# PIC32MX570F512L register map
Vendor: Microchip
Registers are 32-bit, read-write, reset 0x0 unless marked. A register's access mark holds for its fields unless they carry their own. Addresses are absolute, and some are shared; only a register's first bit layout is shown; [hi:lo] are bit positions; {n}, {i} and the like mark numbered series.

## TRAN_Ports
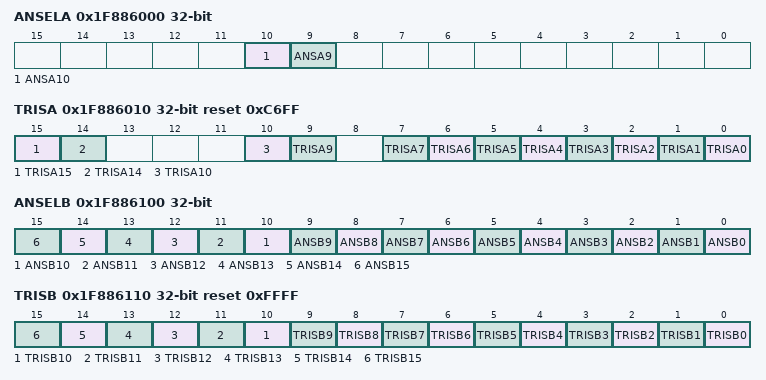
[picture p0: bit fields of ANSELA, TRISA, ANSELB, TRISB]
0x1F886000 ANSELA reset not defined — (power-on value ---------------------xx---------)
  [10] ANSA10, [9] ANSA9
0x1F886010 TRISA reset 0xC6FF
  [15] TRISA15, [14] TRISA14, [10] TRISA10, [9] TRISA9, [n] TRISA{n} (n=0..7)
0x1F886100 ANSELB reset not defined — (power-on value ----------------xxxxxxxxxxxxxxxx)
  [n] ANSB{n} (n=0..15)
0x1F886110 TRISB reset 0xFFFF
  [n] TRISB{n} (n=0..15)
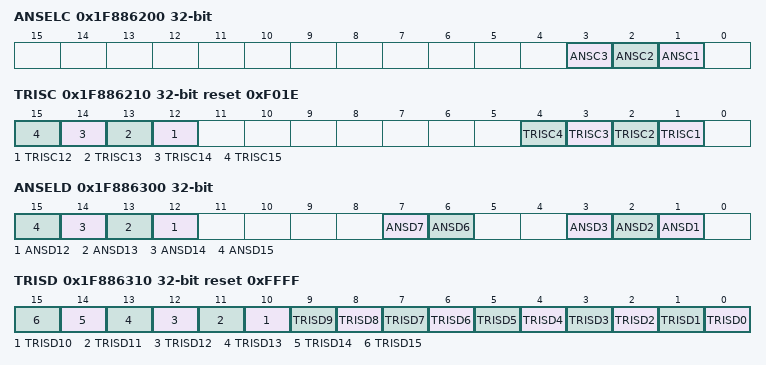
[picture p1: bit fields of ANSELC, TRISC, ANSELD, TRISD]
0x1F886200 ANSELC reset not defined — (power-on value ----------------------------xxx-)
  [3] ANSC3, [2] ANSC2, [1] ANSC1
0x1F886210 TRISC reset 0xF01E
  [n] TRISC{n} (n=12..15), [n] TRISC{n} (n=1..4)
0x1F886300 ANSELD reset not defined — (power-on value ----------------xxxx----xx--xxx-)
  [n] ANSD{n} (n=12..15), [7] ANSD7, [6] ANSD6, [3] ANSD3, [2] ANSD2, [1] ANSD1
0x1F886310 TRISD reset 0xFFFF
  [n] TRISD{n} (n=0..15)
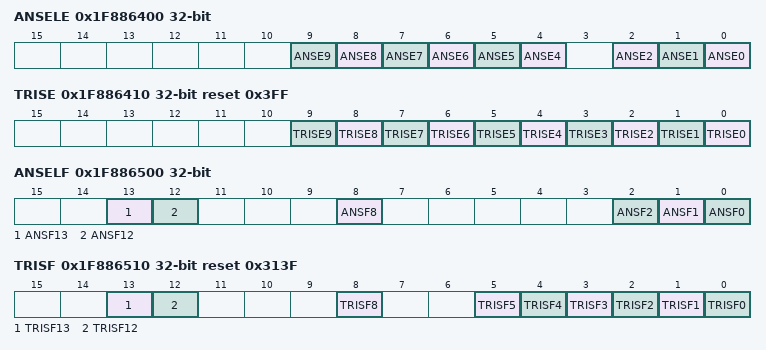
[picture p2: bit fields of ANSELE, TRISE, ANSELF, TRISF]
0x1F886400 ANSELE reset not defined — (power-on value ----------------------xxxxxx-xxx)
  [n] ANSE{n} (n=4..9), [2] ANSE2, [1] ANSE1, [0] ANSE0
0x1F886410 TRISE reset 0x3FF
  [n] TRISE{n} (n=0..9)
0x1F886500 ANSELF reset not defined — (power-on value ------------------xx---x-----xxx)
  [13] ANSF13, [12] ANSF12, [8] ANSF8, [2] ANSF2, [1] ANSF1, [0] ANSF0
0x1F886510 TRISF reset 0x313F
  [13] TRISF13, [12] TRISF12, [8] TRISF8, [n] TRISF{n} (n=0..5)
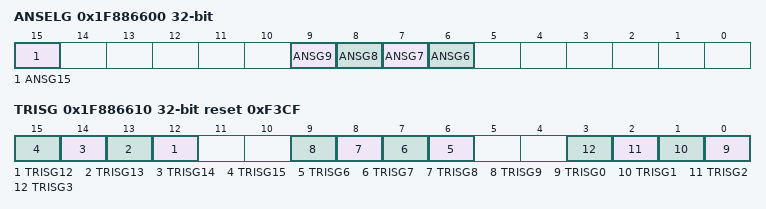
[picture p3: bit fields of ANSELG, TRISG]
0x1F886600 ANSELG reset not defined — (power-on value ----------------x-----xxxx------)
  [15] ANSG15, [n] ANSG{n} (n=6..9)
0x1F886610 TRISG reset 0xF3CF
  [n] TRISG{n} (n=12..15), [n] TRISG{n} (n=6..9), [n] TRISG{n} (n=0..3)

## PORTA
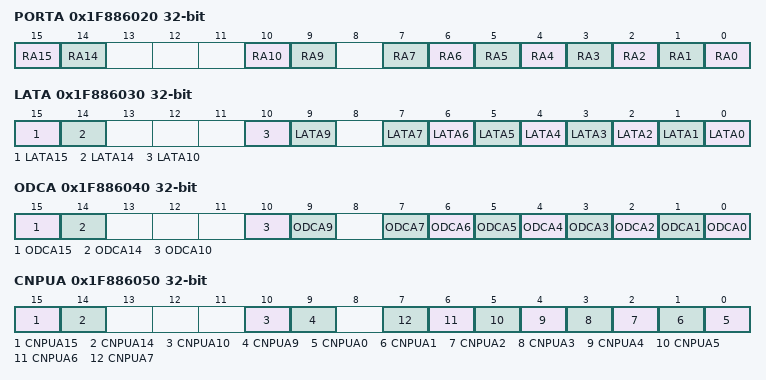
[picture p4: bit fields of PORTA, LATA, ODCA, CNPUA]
0x1F886020 PORTA reset not defined — (power-on value ----------------xx---xx-xxxxxxxx)
  [15] RA15, [14] RA14, [10] RA10, [9] RA9, [n] RA{n} (n=0..7)
0x1F886030 LATA reset not defined — (power-on value ----------------xx---xx-xxxxxxxx)
  [15] LATA15, [14] LATA14, [10] LATA10, [9] LATA9, [n] LATA{n} (n=0..7)
0x1F886040 ODCA
  [15] ODCA15, [14] ODCA14, [10] ODCA10, [9] ODCA9, [n] ODCA{n} (n=0..7)
0x1F886050 CNPUA reset not defined — (power-on value ----------------xx---xx-xxxxxxxx)
  [15] CNPUA15, [14] CNPUA14, [10] CNPUA10, [9] CNPUA9, [n] CNPUA{n} (n=0..7)
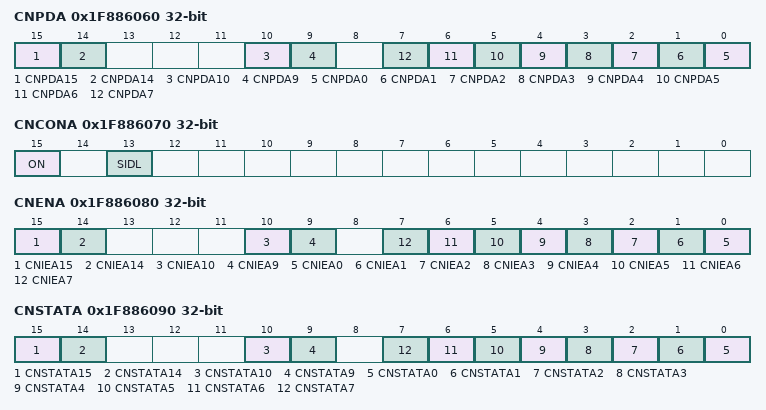
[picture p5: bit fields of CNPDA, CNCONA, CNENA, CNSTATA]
0x1F886060 CNPDA reset not defined — (power-on value ----------------xx---xx-xxxxxxxx)
  [15] CNPDA15, [14] CNPDA14, [10] CNPDA10, [9] CNPDA9, [n] CNPDA{n} (n=0..7)
0x1F886070 CNCONA
  [15] ON, [13] SIDL
0x1F886080 CNENA reset not defined — (power-on value 0000000000------xx---xx-xxxxxxxx)
  [15] CNIEA15, [14] CNIEA14, [10] CNIEA10, [9] CNIEA9, [n] CNIEA{n} (n=0..7)
0x1F886090 CNSTATA reset not defined — (power-on value ----------------xx---xx-xxxxxxxx)
  [15] CNSTATA15, [14] CNSTATA14, [10] CNSTATA10, [9] CNSTATA9, [n] CNSTATA{n} (n=0..7)

## PORTB
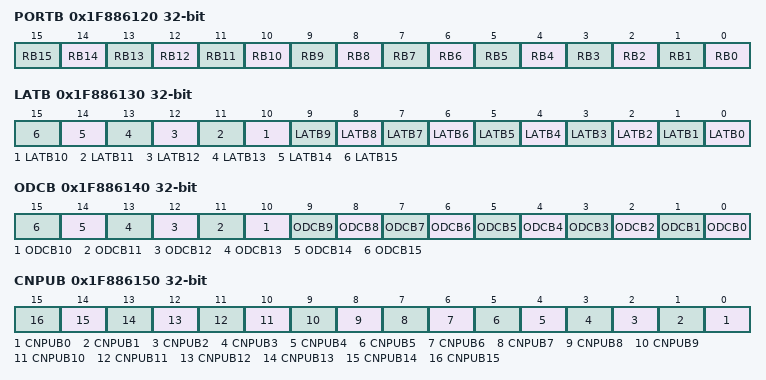
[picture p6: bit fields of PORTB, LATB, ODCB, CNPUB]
0x1F886120 PORTB reset not defined — (power-on value ----------------xxxxxxxxxxxxxxxx)
  [n] RB{n} (n=0..15)
0x1F886130 LATB reset not defined — (power-on value ----------------xxxxxxxxxxxxxxxx)
  [n] LATB{n} (n=0..15)
0x1F886140 ODCB
  [n] ODCB{n} (n=0..15)
0x1F886150 CNPUB reset not defined — (power-on value ----------------xxxxxxxxxxxxxxxx)
  [n] CNPUB{n} (n=0..15)
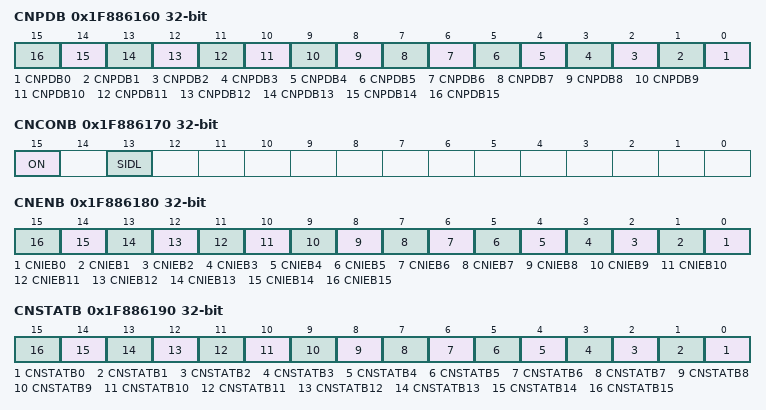
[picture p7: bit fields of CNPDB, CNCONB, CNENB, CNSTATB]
0x1F886160 CNPDB reset not defined — (power-on value ----------------xxxxxxxxxxxxxxxx)
  [n] CNPDB{n} (n=0..15)
0x1F886170 CNCONB
  [15] ON, [13] SIDL
0x1F886180 CNENB reset not defined — (power-on value 0000000000------xxxxxxxxxxxxxxxx)
  [n] CNIEB{n} (n=0..15)
0x1F886190 CNSTATB reset not defined — (power-on value ----------------xxxxxxxxxxxxxxxx)
  [n] CNSTATB{n} (n=0..15)

## PORTC
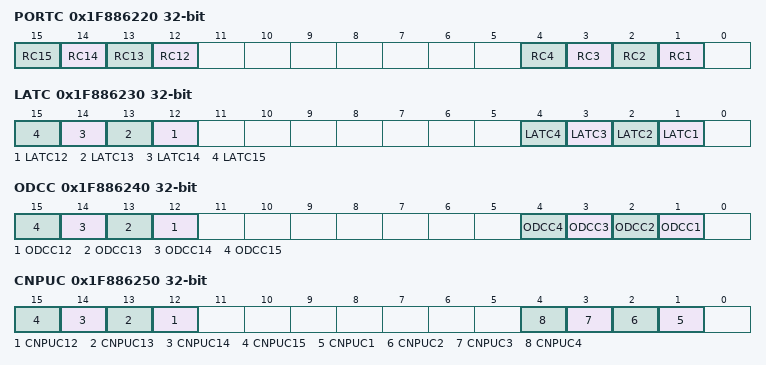
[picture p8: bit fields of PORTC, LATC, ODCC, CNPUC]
0x1F886220 PORTC reset not defined — (power-on value ----------------xxxx-------xxxx-)
  [n] RC{n} (n=12..15), [n] RC{n} (n=1..4)
0x1F886230 LATC reset not defined — (power-on value ----------------xxxx-------xxxx-)
  [n] LATC{n} (n=12..15), [n] LATC{n} (n=1..4)
0x1F886240 ODCC
  [n] ODCC{n} (n=12..15), [n] ODCC{n} (n=1..4)
0x1F886250 CNPUC reset not defined — (power-on value ----------------xxxx-------xxxx-)
  [n] CNPUC{n} (n=12..15), [n] CNPUC{n} (n=1..4)
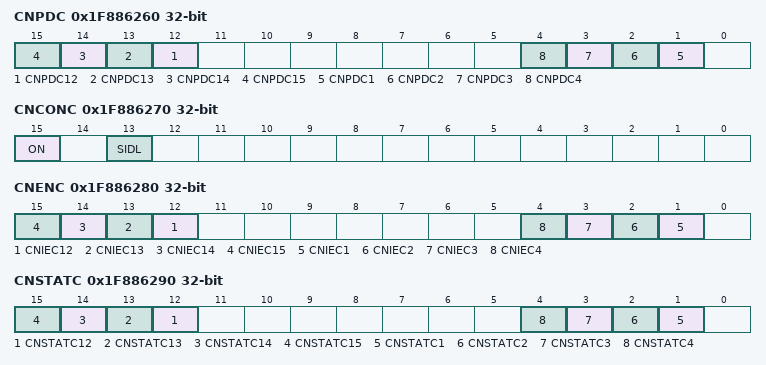
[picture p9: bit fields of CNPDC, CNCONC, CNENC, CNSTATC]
0x1F886260 CNPDC reset not defined — (power-on value ----------------xxxx-------xxxx-)
  [n] CNPDC{n} (n=12..15), [n] CNPDC{n} (n=1..4)
0x1F886270 CNCONC
  [15] ON, [13] SIDL
0x1F886280 CNENC reset not defined — (power-on value 0000000000------xxxx-------xxxx-)
  [n] CNIEC{n} (n=12..15), [n] CNIEC{n} (n=1..4)
0x1F886290 CNSTATC reset not defined — (power-on value ----------------xxxx-------xxxx-)
  [n] CNSTATC{n} (n=12..15), [n] CNSTATC{n} (n=1..4)
